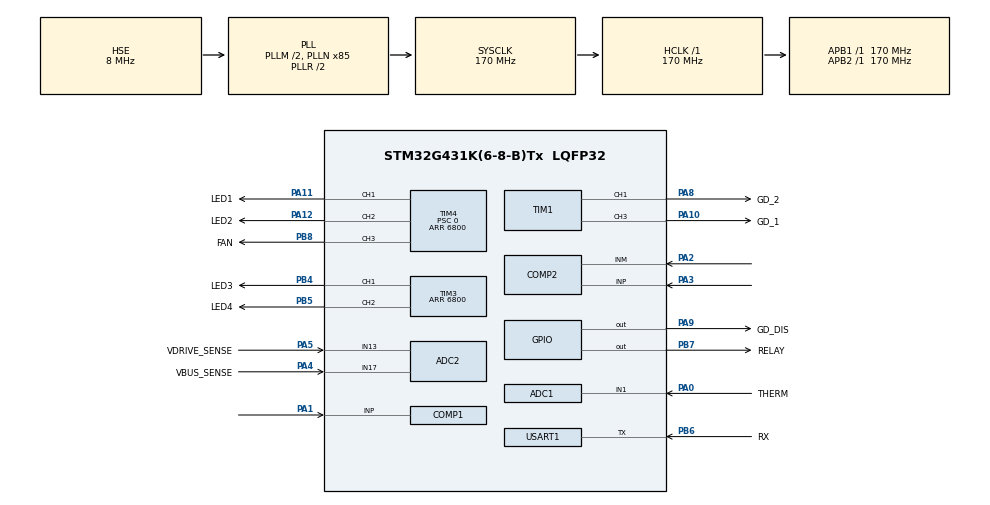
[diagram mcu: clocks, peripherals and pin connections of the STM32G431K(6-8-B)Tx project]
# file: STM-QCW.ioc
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ADC1.Channel-0\#ChannelRegularConversion=ADC_CHANNEL_1
ADC1.Channel-1\#ChannelRegularConversion=ADC_CHANNEL_TEMPSENSOR_ADC1
ADC1.Channel-2\#ChannelRegularConversion=ADC_CHANNEL_VREFINT
ADC1.ClockPrescaler=ADC_CLOCK_ASYNC_DIV4
ADC1.ContinuousConvMode=DISABLE
ADC1.DMAContinuousRequests=ENABLE
ADC1.EOCSelection=ADC_EOC_SEQ_CONV
ADC1.ExternalTrigConv=ADC_EXTERNALTRIG_T15_TRGO
ADC1.NbrOfConversion=3
ADC1.NbrOfConversionFlag=1
ADC1.OffsetNumber-0\#ChannelRegularConversion=ADC_OFFSET_NONE
ADC1.OffsetNumber-1\#ChannelRegularConversion=ADC_OFFSET_NONE
ADC1.OffsetNumber-2\#ChannelRegularConversion=ADC_OFFSET_NONE
ADC1.OversamplingMode=DISABLE
ADC1.Rank-0\#ChannelRegularConversion=1
ADC1.Rank-1\#ChannelRegularConversion=2
ADC1.Rank-2\#ChannelRegularConversion=3
ADC1.SamplingTime-0\#ChannelRegularConversion=ADC_SAMPLETIME_92CYCLES_5
ADC1.SamplingTime-1\#ChannelRegularConversion=ADC_SAMPLETIME_92CYCLES_5
ADC1.SamplingTime-2\#ChannelRegularConversion=ADC_SAMPLETIME_92CYCLES_5
ADC1.master=1
ADC2.Channel-0\#ChannelRegularConversion=ADC_CHANNEL_17
ADC2.Channel-1\#ChannelRegularConversion=ADC_CHANNEL_13
ADC2.ClockPrescaler=ADC_CLOCK_ASYNC_DIV4
ADC2.ContinuousConvMode=DISABLE
ADC2.DMAContinuousRequests=ENABLE
ADC2.ExternalTrigConv=ADC_EXTERNALTRIG_T15_TRGO
ADC2.NbrOfConversion=2
ADC2.NbrOfConversionFlag=1
ADC2.OffsetNumber-0\#ChannelRegularConversion=ADC_OFFSET_NONE
ADC2.OffsetNumber-1\#ChannelRegularConversion=ADC_OFFSET_NONE
ADC2.Rank-0\#ChannelRegularConversion=1
ADC2.Rank-1\#ChannelRegularConversion=2
ADC2.SamplingTime-0\#ChannelRegularConversion=ADC_SAMPLETIME_247CYCLES_5
ADC2.SamplingTime-1\#ChannelRegularConversion=ADC_SAMPLETIME_92CYCLES_5
COMP1.Hysteresis=COMP_HYSTERESIS_10MV
COMP1.TriggerMode=COMP_TRIGGERMODE_IT_RISING
COMP2.Hysteresis=COMP_HYSTERESIS_70MV
COMP2.TriggerMode=COMP_TRIGGERMODE_NONE
Dma.ADC1.0.Direction=DMA_PERIPH_TO_MEMORY
Dma.ADC1.0.EventEnable=DISABLE
Dma.ADC1.0.Instance=DMA1_Channel1
Dma.ADC1.0.MemDataAlignment=DMA_MDATAALIGN_HALFWORD
Dma.ADC1.0.MemInc=DMA_MINC_ENABLE
Dma.ADC1.0.Mode=DMA_CIRCULAR
Dma.ADC1.0.PeriphDataAlignment=DMA_PDATAALIGN_HALFWORD
Dma.ADC1.0.PeriphInc=DMA_PINC_DISABLE
Dma.ADC1.0.Polarity=HAL_DMAMUX_REQ_GEN_RISING
Dma.ADC1.0.Priority=DMA_PRIORITY_LOW
Dma.ADC1.0.RequestNumber=1
Dma.ADC1.0.SignalID=NONE
Dma.ADC1.0.SyncEnable=DISABLE
Dma.ADC1.0.SyncPolarity=HAL_DMAMUX_SYNC_NO_EVENT
Dma.ADC1.0.SyncRequestNumber=1
Dma.ADC1.0.SyncSignalID=NONE
Dma.ADC2.1.Direction=DMA_PERIPH_TO_MEMORY
Dma.ADC2.1.EventEnable=DISABLE
Dma.ADC2.1.Instance=DMA1_Channel2
Dma.ADC2.1.MemDataAlignment=DMA_MDATAALIGN_HALFWORD
Dma.ADC2.1.MemInc=DMA_MINC_ENABLE
Dma.ADC2.1.Mode=DMA_CIRCULAR
Dma.ADC2.1.PeriphDataAlignment=DMA_PDATAALIGN_HALFWORD
Dma.ADC2.1.PeriphInc=DMA_PINC_DISABLE
Dma.ADC2.1.Polarity=HAL_DMAMUX_REQ_GEN_RISING
Dma.ADC2.1.Priority=DMA_PRIORITY_LOW
Dma.ADC2.1.RequestNumber=1
Dma.ADC2.1.SignalID=NONE
Dma.ADC2.1.SyncEnable=DISABLE
Dma.ADC2.1.SyncPolarity=HAL_DMAMUX_SYNC_NO_EVENT
Dma.ADC2.1.SyncRequestNumber=1
Dma.ADC2.1.SyncSignalID=NONE
Dma.Request0=ADC1
Dma.Request1=ADC2
Mcu.Family=STM32G4
Mcu.Name=STM32G431K(6-8-B)Tx
Mcu.Package=LQFP32
NVIC.ADC1_2_IRQn=true\:0\:0\:false\:false\:true\:true\:true\:true
NVIC.COMP1_2_3_IRQn=true\:0\:0\:false\:false\:true\:false\:true\:true
NVIC.DMA1_Channel1_IRQn=true\:0\:0\:false\:false\:true\:false\:true\:true
NVIC.DMA1_Channel2_IRQn=true\:0\:0\:false\:false\:true\:false\:true\:true
NVIC.PriorityGroup=NVIC_PRIORITYGROUP_4
NVIC.TIM1_BRK_TIM15_IRQn=true\:0\:0\:false\:false\:true\:true\:true\:true
NVIC.TIM1_CC_IRQn=true\:0\:0\:false\:false\:true\:true\:true\:true
NVIC.TIM1_TRG_COM_TIM17_IRQn=true\:0\:0\:false\:false\:true\:true\:true\:true
NVIC.TIM1_UP_TIM16_IRQn=true\:0\:0\:false\:false\:true\:true\:true\:true
NVIC.TIM2_IRQn=true\:0\:0\:false\:false\:true\:true\:true\:true
NVIC.TIM6_DAC_IRQn=true\:0\:0\:false\:false\:true\:true\:true\:true
NVIC.TIM7_IRQn=true\:0\:0\:false\:false\:true\:true\:true\:true
NVIC.TIM8_BRK_IRQn=true\:0\:0\:false\:false\:true\:true\:true\:true
NVIC.TIM8_CC_IRQn=true\:0\:0\:false\:false\:true\:true\:true\:true
NVIC.TIM8_TRG_COM_IRQn=true\:0\:0\:false\:false\:true\:true\:true\:true
NVIC.TIM8_UP_IRQn=true\:0\:0\:false\:false\:true\:true\:true\:true
NVIC.USART1_IRQn=true\:0\:0\:false\:false\:true\:true\:true\:true
PA0.GPIO_Label=THERM
PA0.Mode=IN1-Single-Ended
PA0.Signal=ADC1_IN1
PA1.Mode=INP
PA1.Signal=COMP1_INP
PA10.GPIO_Label=GD_1
PA10.Signal=S_TIM1_CH3
PA11.GPIO_Label=LED1
PA11.Signal=S_TIM4_CH1
PA12.GPIO_Label=LED2
PA12.Signal=S_TIM4_CH2
PA13.Mode=JTAG_4_pins
PA13.Signal=SYS_JTMS-SWDIO
PA14.Mode=JTAG_4_pins
PA14.Signal=SYS_JTCK-SWCLK
PA15.Mode=JTAG_4_pins
PA15.Signal=SYS_JTDI
PA2.Mode=INM
PA2.Signal=COMP2_INM
PA3.Mode=INP
PA3.Signal=COMP2_INP
PA4.GPIO_Label=VBUS_SENSE
PA4.Mode=IN17-Single-Ended
PA4.Signal=ADC2_IN17
PA5.GPIO_Label=VDRIVE_SENSE
PA5.Mode=IN13-Single-Ended
PA5.Signal=ADC2_IN13
PA8.GPIO_Label=GD_2
PA8.Signal=S_TIM1_CH1
PA9.GPIO_Label=GD_DIS
PA9.Signal=GPIO_Output
PB3.Mode=JTAG_4_pins
PB3.Signal=SYS_JTDO-SWO
PB4.GPIO_Label=LED3
PB4.Signal=S_TIM3_CH1
PB5.GPIO_Label=LED4
PB5.Signal=S_TIM3_CH2
PB6.GPIO_Label=RX
PB6.GPIO_PuPd=GPIO_PULLUP
PB6.Mode=Half_duplex(single_wire_mode)
PB6.Signal=USART1_TX
PB7.GPIO_Label=RELAY
PB7.Signal=GPIO_Output
PB8-BOOT0.GPIO_Label=FAN
PB8-BOOT0.GPIO_PuPd=GPIO_PULLDOWN
PB8-BOOT0.Signal=S_TIM4_CH3
PF0-OSC_IN.Mode=HSE-External-Oscillator
PF0-OSC_IN.Signal=RCC_OSC_IN
PF1-OSC_OUT.Mode=HSE-External-Oscillator
PF1-OSC_OUT.Signal=RCC_OSC_OUT
ProjectManager.HeapSize=0x200
ProjectManager.StackSize=0x400
ProjectManager.TargetToolchain=STM32CubeIDE
RCC.ADC12Freq_Value=170000000
RCC.AHBFreq_Value=170000000
RCC.APB1Freq_Value=170000000
RCC.APB1TimFreq_Value=170000000
RCC.APB2Freq_Value=170000000
RCC.APB2TimFreq_Value=170000000
RCC.CortexFreq_Value=170000000
RCC.EXTERNAL_CLOCK_VALUE=12288000
RCC.HCLKFreq_Value=170000000
RCC.HSE_Timout=1000
RCC.HSE_VALUE=8000000
RCC.HSI48_VALUE=48000000
RCC.HSI_VALUE=16000000
RCC.LSE_VALUE=32768
RCC.PLLM=RCC_PLLM_DIV2
RCC.PLLN=85
RCC.PLLSourceVirtual=RCC_PLLSOURCE_HSE
RCC.SYSCLKFreq_VALUE=170000000
RCC.SYSCLKSource=RCC_SYSCLKSOURCE_PLLCLK
RCC.USBFreq_Value=170000000
RCC.VCOOutputFreq_Value=340000000
SH.S_TIM1_CH1.0=TIM1_CH1,PWM Generation1 CH1
SH.S_TIM1_CH3.0=TIM1_CH3,PWM Generation3 CH3
SH.S_TIM3_CH1.0=TIM3_CH1,PWM Generation1 CH1
SH.S_TIM3_CH2.0=TIM3_CH2,PWM Generation2 CH2
SH.S_TIM4_CH1.0=TIM4_CH1,PWM Generation1 CH1
SH.S_TIM4_CH2.0=TIM4_CH2,PWM Generation2 CH2
SH.S_TIM4_CH3.0=TIM4_CH3,PWM Generation3 CH3
TIM1.Channel-PWM\ Generation1\ CH1=TIM_CHANNEL_1
TIM1.Channel-PWM\ Generation2\ No\ Output=TIM_CHANNEL_2
TIM1.Channel-PWM\ Generation3\ CH3=TIM_CHANNEL_3
TIM1.Channel-PWM\ Generation4\ No\ Output=TIM_CHANNEL_4
TIM1.CounterMode=TIM_COUNTERMODE_CENTERALIGNED1
TIM1.OCMode_PWM-PWM\ Generation1\ CH1=TIM_OCMODE_ASSYMETRIC_PWM1
TIM1.OCMode_PWM-PWM\ Generation2\ No\ Output=TIM_OCMODE_ASSYMETRIC_PWM1
TIM1.OCMode_PWM-PWM\ Generation3\ CH3=TIM_OCMODE_ASSYMETRIC_PWM1
TIM1.OCMode_PWM-PWM\ Generation4\ No\ Output=TIM_OCMODE_ASSYMETRIC_PWM1
TIM1.OCPolarity_3=TIM_OCPOLARITY_HIGH
TIM1.OCPolarity_4=TIM_OCPOLARITY_HIGH
TIM1.TIM_MasterOutputTrigger=TIM_TRGO_ENABLE
TIM1.TIM_MasterOutputTrigger2=TIM_TRGO2_OC5REF
TIM15.PeriodNoDither=100-1
TIM15.Prescaler=170-1
TIM15.TIM_MasterOutputTrigger=TIM_TRGO_UPDATE
TIM2.Channel-Input_Capture1_from_TI1_REMAP_TIM2=TIM_CHANNEL_1
TIM2.TIM2_TI1_REMAP-Input_Capture1_from_TI1_REMAP_TIM2=TIM_TIM2_TI1_COMP2
TIM3.Channel-PWM\ Generation1\ CH1=TIM_CHANNEL_1
TIM3.Channel-PWM\ Generation2\ CH2=TIM_CHANNEL_2
TIM3.PeriodNoDither=6800
TIM4.Channel-PWM\ Generation1\ CH1=TIM_CHANNEL_1
TIM4.Channel-PWM\ Generation2\ CH2=TIM_CHANNEL_2
TIM4.Channel-PWM\ Generation3\ CH3=TIM_CHANNEL_3
TIM4.OCMode_PWM-PWM\ Generation3\ CH3=TIM_OCMODE_PWM2
TIM4.PeriodNoDither=6800
TIM4.Prescaler=0
TIM7.PeriodNoDither=10000-1
TIM7.Prescaler=1700-1
TIM8.Channel-PWM\ Generation1\ No\ Output=TIM_CHANNEL_1
TIM8.CounterMode=TIM_COUNTERMODE_CENTERALIGNED1
TIM8.TIM8_ETR_REMAP-TriggerSource_ETR_Remap_TIM8=TIM_TIM8_ETR_COMP2
USART1.Mode=MODE_RX
USART1.RxPinLevelInvertParam=ADVFEATURE_RXINV_DISABLE
USART1.TxPinLevelInvertParam=ADVFEATURE_TXINV_DISABLE
USART1.VirtualMode-Half_duplex(single_wire_mode)=VM_ASYNC
VP_ADC1_TempSens_Input.Mode=IN-TempSens
VP_ADC1_Vref_Input.Mode=IN-Vrefint
VP_COMP1_VS_DAC1OUT1.Mode=INM_DAC1OUT1
VP_DAC1_VS_DACI1.Mode=DAC_OUT1_Int
VP_SYS_VS_DBSignals.Mode=DisableDeadBatterySignals
VP_TIM15_VS_ClockSourceINT.Mode=Internal
VP_TIM1_VS_ClockSourceINT.Mode=Internal
VP_TIM1_VS_no_output2.Mode=PWM Generation2 No Output
VP_TIM1_VS_no_output4.Mode=PWM Generation4 No Output
VP_TIM2_VS_ClockSourceINT.Mode=Internal
VP_TIM2_VS_NoInput1.Mode=Input_Capture1_from_TI1_REMAP_TIM2
VP_TIM3_VS_ClockSourceINT.Mode=Internal
VP_TIM4_VS_ClockSourceINT.Mode=Internal
VP_TIM6_VS_ClockSourceINT.Mode=Enable_Timer
VP_TIM7_VS_ClockSourceINT.Mode=Enable_Timer
VP_TIM8_VS_ClockSourceINT.Mode=Internal
VP_TIM8_VS_ControllerModeReset.Mode=Reset Mode
VP_TIM8_VS_NoETR.Mode=TriggerSource_ETR_Remap_TIM8
VP_TIM8_VS_no_output1.Mode=PWM Generation1 No Output
board=custom

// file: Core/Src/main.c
/* USER CODE BEGIN Header */
/**
  ******************************************************************************
  * @file           : main.c
  * @brief          : Main program body
  ******************************************************************************
  * @attention
  *
  * Copyright (c) 2025 STMicroelectronics.
  * All rights reserved.
  *
  * This software is licensed under terms that can be found in the LICENSE file
  * in the root directory of this software component.
  * If no LICENSE file comes with this software, it is provided AS-IS.
  *
  ******************************************************************************
  */
/* USER CODE END Header */
#include "main.h"

ADC_HandleTypeDef hadc1;
ADC_HandleTypeDef hadc2;
DMA_HandleTypeDef hdma_adc1;
DMA_HandleTypeDef hdma_adc2;

COMP_HandleTypeDef hcomp1;
COMP_HandleTypeDef hcomp2;

DAC_HandleTypeDef hdac1;

TIM_HandleTypeDef htim1;
TIM_HandleTypeDef htim2;
TIM_HandleTypeDef htim3;
TIM_HandleTypeDef htim4;
TIM_HandleTypeDef htim6;
TIM_HandleTypeDef htim7;
TIM_HandleTypeDef htim8;
TIM_HandleTypeDef htim15;

UART_HandleTypeDef huart1;

void SystemClock_Config(void);
static void MX_GPIO_Init(void);
static void MX_DMA_Init(void);
static void MX_ADC1_Init(void);
static void MX_ADC2_Init(void);
static void MX_COMP1_Init(void);
static void MX_COMP2_Init(void);
static void MX_DAC1_Init(void);
static void MX_TIM1_Init(void);
static void MX_USART1_UART_Init(void);
static void MX_TIM2_Init(void);
static void MX_TIM6_Init(void);
static void MX_TIM4_Init(void);
static void MX_TIM3_Init(void);
static void MX_TIM7_Init(void);
static void MX_TIM8_Init(void);
static void MX_TIM15_Init(void);

int main(void)
{

  /* MCU Configuration--------------------------------------------------------*/

  /* Reset of all peripherals, Initializes the Flash interface and the Systick. */
  HAL_Init();

  /* Configure the system clock */
  SystemClock_Config();

  /* Initialize all configured peripherals */
  MX_GPIO_Init();
  MX_DMA_Init();
  MX_ADC1_Init();
  MX_ADC2_Init();
  MX_COMP1_Init();
  MX_COMP2_Init();
  MX_DAC1_Init();
  MX_TIM1_Init();
  MX_USART1_UART_Init();
  MX_TIM2_Init();
  MX_TIM6_Init();
  MX_TIM4_Init();
  MX_TIM3_Init();
  MX_TIM7_Init();
  MX_TIM8_Init();
  MX_TIM15_Init();
  /* USER CODE BEGIN 2 */

  QCW_Init();
  HAL_Delay(1000);
  /* USER CODE END 2 */

  /* Infinite loop */
  while (1)
  {

    /* USER CODE BEGIN 3 */
	  	 HAL_Delay(100);
	  	 StartPulse(1.0f, 150.0f, 30.0f);

  }
  /* USER CODE END 3 */
}

void SystemClock_Config(void)
{
  RCC_OscInitTypeDef RCC_OscInitStruct = {0};
  RCC_ClkInitTypeDef RCC_ClkInitStruct = {0};

  /** Configure the main internal regulator output voltage
  */
  HAL_PWREx_ControlVoltageScaling(PWR_REGULATOR_VOLTAGE_SCALE1_BOOST);

  /** Initializes the RCC Oscillators according to the specified parameters
  * in the RCC_OscInitTypeDef structure.
  */
  RCC_OscInitStruct.OscillatorType = RCC_OSCILLATORTYPE_HSE;
  RCC_OscInitStruct.HSEState = RCC_HSE_ON;
  RCC_OscInitStruct.PLL.PLLState = RCC_PLL_ON;
  RCC_OscInitStruct.PLL.PLLSource = RCC_PLLSOURCE_HSE;
  RCC_OscInitStruct.PLL.PLLM = RCC_PLLM_DIV2;
  RCC_OscInitStruct.PLL.PLLN = 85;
  RCC_OscInitStruct.PLL.PLLP = RCC_PLLP_DIV2;
  RCC_OscInitStruct.PLL.PLLQ = RCC_PLLQ_DIV2;
  RCC_OscInitStruct.PLL.PLLR = RCC_PLLR_DIV2;
  if (HAL_RCC_OscConfig(&RCC_OscInitStruct) != HAL_OK)
  {
    Error_Handler();
  }

  /** Initializes the CPU, AHB and APB buses clocks
  */
  RCC_ClkInitStruct.ClockType = RCC_CLOCKTYPE_HCLK|RCC_CLOCKTYPE_SYSCLK
                              |RCC_CLOCKTYPE_PCLK1|RCC_CLOCKTYPE_PCLK2;
  RCC_ClkInitStruct.SYSCLKSource = RCC_SYSCLKSOURCE_PLLCLK;
  RCC_ClkInitStruct.AHBCLKDivider = RCC_SYSCLK_DIV1;
  RCC_ClkInitStruct.APB1CLKDivider = RCC_HCLK_DIV1;
  RCC_ClkInitStruct.APB2CLKDivider = RCC_HCLK_DIV1;

  if (HAL_RCC_ClockConfig(&RCC_ClkInitStruct, FLASH_LATENCY_4) != HAL_OK)
  {
    Error_Handler();
  }
}

static void MX_ADC1_Init(void)
{

  ADC_MultiModeTypeDef multimode = {0};
  ADC_ChannelConfTypeDef sConfig = {0};

  /** Common config
  */
  hadc1.Instance = ADC1;
  hadc1.Init.ClockPrescaler = ADC_CLOCK_ASYNC_DIV4;
  hadc1.Init.Resolution = ADC_RESOLUTION_12B;
  hadc1.Init.DataAlign = ADC_DATAALIGN_RIGHT;
  hadc1.Init.GainCompensation = 0;
  hadc1.Init.ScanConvMode = ADC_SCAN_ENABLE;
  hadc1.Init.EOCSelection = ADC_EOC_SEQ_CONV;
  hadc1.Init.LowPowerAutoWait = DISABLE;
  hadc1.Init.ContinuousConvMode = DISABLE;
  hadc1.Init.NbrOfConversion = 3;
  hadc1.Init.DiscontinuousConvMode = DISABLE;
  hadc1.Init.ExternalTrigConv = ADC_EXTERNALTRIG_T15_TRGO;
  hadc1.Init.ExternalTrigConvEdge = ADC_EXTERNALTRIGCONVEDGE_RISING;
  hadc1.Init.DMAContinuousRequests = ENABLE;
  hadc1.Init.Overrun = ADC_OVR_DATA_PRESERVED;
  hadc1.Init.OversamplingMode = DISABLE;
  if (HAL_ADC_Init(&hadc1) != HAL_OK)
  {
    Error_Handler();
  }

  /** Configure the ADC multi-mode
  */
  multimode.Mode = ADC_MODE_INDEPENDENT;
  if (HAL_ADCEx_MultiModeConfigChannel(&hadc1, &multimode) != HAL_OK)
  {
    Error_Handler();
  }

  /** Configure Regular Channel
  */
  sConfig.Channel = ADC_CHANNEL_1;
  sConfig.Rank = ADC_REGULAR_RANK_1;
  sConfig.SamplingTime = ADC_SAMPLETIME_92CYCLES_5;
  sConfig.SingleDiff = ADC_SINGLE_ENDED;
  sConfig.OffsetNumber = ADC_OFFSET_NONE;
  sConfig.Offset = 0;
  if (HAL_ADC_ConfigChannel(&hadc1, &sConfig) != HAL_OK)
  {
    Error_Handler();
  }

  /** Configure Regular Channel
  */
  sConfig.Channel = ADC_CHANNEL_TEMPSENSOR_ADC1;
  sConfig.Rank = ADC_REGULAR_RANK_2;
  if (HAL_ADC_ConfigChannel(&hadc1, &sConfig) != HAL_OK)
  {
    Error_Handler();
  }

  /** Configure Regular Channel
  */
  sConfig.Channel = ADC_CHANNEL_VREFINT;
  sConfig.Rank = ADC_REGULAR_RANK_3;
  if (HAL_ADC_ConfigChannel(&hadc1, &sConfig) != HAL_OK)
  {
    Error_Handler();
  }

}

static void MX_ADC2_Init(void)
{

  ADC_ChannelConfTypeDef sConfig = {0};

  /** Common config
  */
  hadc2.Instance = ADC2;
  hadc2.Init.ClockPrescaler = ADC_CLOCK_ASYNC_DIV4;
  hadc2.Init.Resolution = ADC_RESOLUTION_12B;
  hadc2.Init.DataAlign = ADC_DATAALIGN_RIGHT;
  hadc2.Init.GainCompensation = 0;
  hadc2.Init.ScanConvMode = ADC_SCAN_ENABLE;
  hadc2.Init.EOCSelection = ADC_EOC_SINGLE_CONV;
  hadc2.Init.LowPowerAutoWait = DISABLE;
  hadc2.Init.ContinuousConvMode = DISABLE;
  hadc2.Init.NbrOfConversion = 2;
  hadc2.Init.DiscontinuousConvMode = DISABLE;
  hadc2.Init.ExternalTrigConv = ADC_EXTERNALTRIG_T15_TRGO;
  hadc2.Init.ExternalTrigConvEdge = ADC_EXTERNALTRIGCONVEDGE_RISING;
  hadc2.Init.DMAContinuousRequests = ENABLE;
  hadc2.Init.Overrun = ADC_OVR_DATA_PRESERVED;
  hadc2.Init.OversamplingMode = DISABLE;
  if (HAL_ADC_Init(&hadc2) != HAL_OK)
  {
    Error_Handler();
  }

  /** Configure Regular Channel
  */
  sConfig.Channel = ADC_CHANNEL_17;
  sConfig.Rank = ADC_REGULAR_RANK_1;
  sConfig.SamplingTime = ADC_SAMPLETIME_247CYCLES_5;
  sConfig.SingleDiff = ADC_SINGLE_ENDED;
  sConfig.OffsetNumber = ADC_OFFSET_NONE;
  sConfig.Offset = 0;
  if (HAL_ADC_ConfigChannel(&hadc2, &sConfig) != HAL_OK)
  {
    Error_Handler();
  }

  /** Configure Regular Channel
  */
  sConfig.Channel = ADC_CHANNEL_13;
  sConfig.Rank = ADC_REGULAR_RANK_2;
  sConfig.SamplingTime = ADC_SAMPLETIME_92CYCLES_5;
  if (HAL_ADC_ConfigChannel(&hadc2, &sConfig) != HAL_OK)
  {
    Error_Handler();
  }

}

static void MX_COMP1_Init(void)
{

  hcomp1.Instance = COMP1;
  hcomp1.Init.InputPlus = COMP_INPUT_PLUS_IO1;
  hcomp1.Init.InputMinus = COMP_INPUT_MINUS_DAC1_CH1;
  hcomp1.Init.OutputPol = COMP_OUTPUTPOL_NONINVERTED;
  hcomp1.Init.Hysteresis = COMP_HYSTERESIS_10MV;
  hcomp1.Init.BlankingSrce = COMP_BLANKINGSRC_NONE;
  hcomp1.Init.TriggerMode = COMP_TRIGGERMODE_IT_RISING;
  if (HAL_COMP_Init(&hcomp1) != HAL_OK)
  {
    Error_Handler();
  }

}

static void MX_COMP2_Init(void)
{

  hcomp2.Instance = COMP2;
  hcomp2.Init.InputPlus = COMP_INPUT_PLUS_IO2;
  hcomp2.Init.InputMinus = COMP_INPUT_MINUS_IO2;
  hcomp2.Init.OutputPol = COMP_OUTPUTPOL_NONINVERTED;
  hcomp2.Init.Hysteresis = COMP_HYSTERESIS_70MV;
  hcomp2.Init.BlankingSrce = COMP_BLANKINGSRC_NONE;
  hcomp2.Init.TriggerMode = COMP_TRIGGERMODE_NONE;
  if (HAL_COMP_Init(&hcomp2) != HAL_OK)
  {
    Error_Handler();
  }

}

static void MX_DAC1_Init(void)
{

  DAC_ChannelConfTypeDef sConfig = {0};

  /** DAC Initialization
  */
  hdac1.Instance = DAC1;
  if (HAL_DAC_Init(&hdac1) != HAL_OK)
  {
    Error_Handler();
  }

  /** DAC channel OUT1 config
  */
  sConfig.DAC_HighFrequency = DAC_HIGH_FREQUENCY_INTERFACE_MODE_AUTOMATIC;
  sConfig.DAC_DMADoubleDataMode = DISABLE;
  sConfig.DAC_SignedFormat = DISABLE;
  sConfig.DAC_SampleAndHold = DAC_SAMPLEANDHOLD_DISABLE;
  sConfig.DAC_Trigger = DAC_TRIGGER_NONE;
  sConfig.DAC_Trigger2 = DAC_TRIGGER_NONE;
  sConfig.DAC_OutputBuffer = DAC_OUTPUTBUFFER_DISABLE;
  sConfig.DAC_ConnectOnChipPeripheral = DAC_CHIPCONNECT_INTERNAL;
  sConfig.DAC_UserTrimming = DAC_TRIMMING_FACTORY;
  if (HAL_DAC_ConfigChannel(&hdac1, &sConfig, DAC_CHANNEL_1) != HAL_OK)
  {
    Error_Handler();
  }

}

static void MX_TIM1_Init(void)
{

  TIM_ClockConfigTypeDef sClockSourceConfig = {0};
  TIM_MasterConfigTypeDef sMasterConfig = {0};
  TIM_OC_InitTypeDef sConfigOC = {0};
  TIM_BreakDeadTimeConfigTypeDef sBreakDeadTimeConfig = {0};

  htim1.Instance = TIM1;
  htim1.Init.Prescaler = 0;
  htim1.Init.CounterMode = TIM_COUNTERMODE_CENTERALIGNED1;
  htim1.Init.Period = 65535;
  htim1.Init.ClockDivision = TIM_CLOCKDIVISION_DIV1;
  htim1.Init.RepetitionCounter = 0;
  htim1.Init.AutoReloadPreload = TIM_AUTORELOAD_PRELOAD_DISABLE;
  if (HAL_TIM_Base_Init(&htim1) != HAL_OK)
  {
    Error_Handler();
  }
  sClockSourceConfig.ClockSource = TIM_CLOCKSOURCE_INTERNAL;
  if (HAL_TIM_ConfigClockSource(&htim1, &sClockSourceConfig) != HAL_OK)
  {
    Error_Handler();
  }
  if (HAL_TIM_PWM_Init(&htim1) != HAL_OK)
  {
    Error_Handler();
  }
  sMasterConfig.MasterOutputTrigger = TIM_TRGO_ENABLE;
  sMasterConfig.MasterOutputTrigger2 = TIM_TRGO2_OC5REF;
  sMasterConfig.MasterSlaveMode = TIM_MASTERSLAVEMODE_DISABLE;
  if (HAL_TIMEx_MasterConfigSynchronization(&htim1, &sMasterConfig) != HAL_OK)
  {
    Error_Handler();
  }
  sConfigOC.OCMode = TIM_OCMODE_ASSYMETRIC_PWM1;
  sConfigOC.Pulse = 0;
  sConfigOC.OCPolarity = TIM_OCPOLARITY_HIGH;
  sConfigOC.OCNPolarity = TIM_OCNPOLARITY_HIGH;
  sConfigOC.OCFastMode = TIM_OCFAST_DISABLE;
  sConfigOC.OCIdleState = TIM_OCIDLESTATE_RESET;
  sConfigOC.OCNIdleState = TIM_OCNIDLESTATE_RESET;
  if (HAL_TIM_PWM_ConfigChannel(&htim1, &sConfigOC, TIM_CHANNEL_1) != HAL_OK)
  {
    Error_Handler();
  }
  if (HAL_TIM_PWM_ConfigChannel(&htim1, &sConfigOC, TIM_CHANNEL_2) != HAL_OK)
  {
    Error_Handler();
  }
  if (HAL_TIM_PWM_ConfigChannel(&htim1, &sConfigOC, TIM_CHANNEL_3) != HAL_OK)
  {
    Error_Handler();
  }
  if (HAL_TIM_PWM_ConfigChannel(&htim1, &sConfigOC, TIM_CHANNEL_4) != HAL_OK)
  {
    Error_Handler();
  }
  sBreakDeadTimeConfig.OffStateRunMode = TIM_OSSR_DISABLE;
  sBreakDeadTimeConfig.OffStateIDLEMode = TIM_OSSI_DISABLE;
  sBreakDeadTimeConfig.LockLevel = TIM_LOCKLEVEL_OFF;
  sBreakDeadTimeConfig.DeadTime = 0;
  sBreakDeadTimeConfig.BreakState = TIM_BREAK_DISABLE;
  sBreakDeadTimeConfig.BreakPolarity = TIM_BREAKPOLARITY_HIGH;
  sBreakDeadTimeConfig.BreakFilter = 0;
  sBreakDeadTimeConfig.BreakAFMode = TIM_BREAK_AFMODE_INPUT;
  sBreakDeadTimeConfig.Break2State = TIM_BREAK2_DISABLE;
  sBreakDeadTimeConfig.Break2Polarity = TIM_BREAK2POLARITY_HIGH;
  sBreakDeadTimeConfig.Break2Filter = 0;
  sBreakDeadTimeConfig.Break2AFMode = TIM_BREAK_AFMODE_INPUT;
  sBreakDeadTimeConfig.AutomaticOutput = TIM_AUTOMATICOUTPUT_DISABLE;
  if (HAL_TIMEx_ConfigBreakDeadTime(&htim1, &sBreakDeadTimeConfig) != HAL_OK)
  {
    Error_Handler();
  }
  HAL_TIM_MspPostInit(&htim1);

}

static void MX_TIM2_Init(void)
{

  TIM_ClockConfigTypeDef sClockSourceConfig = {0};
  TIM_MasterConfigTypeDef sMasterConfig = {0};
  TIM_IC_InitTypeDef sConfigIC = {0};

  htim2.Instance = TIM2;
  htim2.Init.Prescaler = 0;
  htim2.Init.CounterMode = TIM_COUNTERMODE_UP;
  htim2.Init.Period = 4294967295;
  htim2.Init.ClockDivision = TIM_CLOCKDIVISION_DIV1;
  htim2.Init.AutoReloadPreload = TIM_AUTORELOAD_PRELOAD_DISABLE;
  if (HAL_TIM_Base_Init(&htim2) != HAL_OK)
  {
    Error_Handler();
  }
  sClockSourceConfig.ClockSource = TIM_CLOCKSOURCE_INTERNAL;
  if (HAL_TIM_ConfigClockSource(&htim2, &sClockSourceConfig) != HAL_OK)
  {
    Error_Handler();
  }
  if (HAL_TIM_IC_Init(&htim2) != HAL_OK)
  {
    Error_Handler();
  }
  sMasterConfig.MasterOutputTrigger = TIM_TRGO_RESET;
  sMasterConfig.MasterSlaveMode = TIM_MASTERSLAVEMODE_DISABLE;
  if (HAL_TIMEx_MasterConfigSynchronization(&htim2, &sMasterConfig) != HAL_OK)
  {
    Error_Handler();
  }
  sConfigIC.ICPolarity = TIM_INPUTCHANNELPOLARITY_RISING;
  sConfigIC.ICSelection = TIM_ICSELECTION_DIRECTTI;
  sConfigIC.ICPrescaler = TIM_ICPSC_DIV1;
  sConfigIC.ICFilter = 0;
  if (HAL_TIM_IC_ConfigChannel(&htim2, &sConfigIC, TIM_CHANNEL_1) != HAL_OK)
  {
    Error_Handler();
  }
  if (HAL_TIMEx_TISelection(&htim2, TIM_TIM2_TI1_COMP2, TIM_CHANNEL_1) != HAL_OK)
  {
    Error_Handler();
  }

}

static void MX_TIM3_Init(void)
{

  TIM_ClockConfigTypeDef sClockSourceConfig = {0};
  TIM_MasterConfigTypeDef sMasterConfig = {0};
  TIM_OC_InitTypeDef sConfigOC = {0};

  htim3.Instance = TIM3;
  htim3.Init.Prescaler = 0;
  htim3.Init.CounterMode = TIM_COUNTERMODE_UP;
  htim3.Init.Period = 6800;
  htim3.Init.ClockDivision = TIM_CLOCKDIVISION_DIV1;
  htim3.Init.AutoReloadPreload = TIM_AUTORELOAD_PRELOAD_DISABLE;
  if (HAL_TIM_Base_Init(&htim3) != HAL_OK)
  {
    Error_Handler();
  }
  sClockSourceConfig.ClockSource = TIM_CLOCKSOURCE_INTERNAL;
  if (HAL_TIM_ConfigClockSource(&htim3, &sClockSourceConfig) != HAL_OK)
  {
    Error_Handler();
  }
  if (HAL_TIM_PWM_Init(&htim3) != HAL_OK)
  {
    Error_Handler();
  }
  sMasterConfig.MasterOutputTrigger = TIM_TRGO_RESET;
  sMasterConfig.MasterSlaveMode = TIM_MASTERSLAVEMODE_DISABLE;
  if (HAL_TIMEx_MasterConfigSynchronization(&htim3, &sMasterConfig) != HAL_OK)
  {
    Error_Handler();
  }
  sConfigOC.OCMode = TIM_OCMODE_PWM1;
  sConfigOC.Pulse = 0;
  sConfigOC.OCPolarity = TIM_OCPOLARITY_HIGH;
  sConfigOC.OCFastMode = TIM_OCFAST_DISABLE;
  if (HAL_TIM_PWM_ConfigChannel(&htim3, &sConfigOC, TIM_CHANNEL_1) != HAL_OK)
  {
    Error_Handler();
  }
  if (HAL_TIM_PWM_ConfigChannel(&htim3, &sConfigOC, TIM_CHANNEL_2) != HAL_OK)
  {
    Error_Handler();
  }
  HAL_TIM_MspPostInit(&htim3);

}

static void MX_TIM4_Init(void)
{

  TIM_ClockConfigTypeDef sClockSourceConfig = {0};
  TIM_MasterConfigTypeDef sMasterConfig = {0};
  TIM_OC_InitTypeDef sConfigOC = {0};

  htim4.Instance = TIM4;
  htim4.Init.Prescaler = 0;
  htim4.Init.CounterMode = TIM_COUNTERMODE_UP;
  htim4.Init.Period = 6800;
  htim4.Init.ClockDivision = TIM_CLOCKDIVISION_DIV1;
  htim4.Init.AutoReloadPreload = TIM_AUTORELOAD_PRELOAD_DISABLE;
  if (HAL_TIM_Base_Init(&htim4) != HAL_OK)
  {
    Error_Handler();
  }
  sClockSourceConfig.ClockSource = TIM_CLOCKSOURCE_INTERNAL;
  if (HAL_TIM_ConfigClockSource(&htim4, &sClockSourceConfig) != HAL_OK)
  {
    Error_Handler();
  }
  if (HAL_TIM_PWM_Init(&htim4) != HAL_OK)
  {
    Error_Handler();
  }
  sMasterConfig.MasterOutputTrigger = TIM_TRGO_RESET;
  sMasterConfig.MasterSlaveMode = TIM_MASTERSLAVEMODE_DISABLE;
  if (HAL_TIMEx_MasterConfigSynchronization(&htim4, &sMasterConfig) != HAL_OK)
  {
    Error_Handler();
  }
  sConfigOC.OCMode = TIM_OCMODE_PWM1;
  sConfigOC.Pulse = 0;
  sConfigOC.OCPolarity = TIM_OCPOLARITY_HIGH;
  sConfigOC.OCFastMode = TIM_OCFAST_DISABLE;
  if (HAL_TIM_PWM_ConfigChannel(&htim4, &sConfigOC, TIM_CHANNEL_1) != HAL_OK)
  {
    Error_Handler();
  }
  if (HAL_TIM_PWM_ConfigChannel(&htim4, &sConfigOC, TIM_CHANNEL_2) != HAL_OK)
  {
    Error_Handler();
  }
  sConfigOC.OCMode = TIM_OCMODE_PWM2;
  if (HAL_TIM_PWM_ConfigChannel(&htim4, &sConfigOC, TIM_CHANNEL_3) != HAL_OK)
  {
    Error_Handler();
  }
  HAL_TIM_MspPostInit(&htim4);

}

static void MX_TIM6_Init(void)
{

  TIM_MasterConfigTypeDef sMasterConfig = {0};

  htim6.Instance = TIM6;
  htim6.Init.Prescaler = 0;
  htim6.Init.CounterMode = TIM_COUNTERMODE_UP;
  htim6.Init.Period = 65535;
  htim6.Init.AutoReloadPreload = TIM_AUTORELOAD_PRELOAD_DISABLE;
  if (HAL_TIM_Base_Init(&htim6) != HAL_OK)
  {
    Error_Handler();
  }
  sMasterConfig.MasterOutputTrigger = TIM_TRGO_RESET;
  sMasterConfig.MasterSlaveMode = TIM_MASTERSLAVEMODE_DISABLE;
  if (HAL_TIMEx_MasterConfigSynchronization(&htim6, &sMasterConfig) != HAL_OK)
  {
    Error_Handler();
  }

}

static void MX_TIM7_Init(void)
{

  TIM_MasterConfigTypeDef sMasterConfig = {0};

  htim7.Instance = TIM7;
  htim7.Init.Prescaler = 1700-1;
  htim7.Init.CounterMode = TIM_COUNTERMODE_UP;
  htim7.Init.Period = 9999;
  htim7.Init.AutoReloadPreload = TIM_AUTORELOAD_PRELOAD_DISABLE;
  if (HAL_TIM_Base_Init(&htim7) != HAL_OK)
  {
    Error_Handler();
  }
  sMasterConfig.MasterOutputTrigger = TIM_TRGO_RESET;
  sMasterConfig.MasterSlaveMode = TIM_MASTERSLAVEMODE_DISABLE;
  if (HAL_TIMEx_MasterConfigSynchronization(&htim7, &sMasterConfig) != HAL_OK)
  {
    Error_Handler();
  }

}

static void MX_TIM8_Init(void)
{

  TIM_ClockConfigTypeDef sClockSourceConfig = {0};
  TIM_SlaveConfigTypeDef sSlaveConfig = {0};
  TIM_MasterConfigTypeDef sMasterConfig = {0};
  TIM_OC_InitTypeDef sConfigOC = {0};
  TIM_BreakDeadTimeConfigTypeDef sBreakDeadTimeConfig = {0};

  htim8.Instance = TIM8;
  htim8.Init.Prescaler = 0;
  htim8.Init.CounterMode = TIM_COUNTERMODE_CENTERALIGNED1;
  htim8.Init.Period = 65535;
  htim8.Init.ClockDivision = TIM_CLOCKDIVISION_DIV1;
  htim8.Init.RepetitionCounter = 0;
  htim8.Init.AutoReloadPreload = TIM_AUTORELOAD_PRELOAD_DISABLE;
  if (HAL_TIM_Base_Init(&htim8) != HAL_OK)
  {
    Error_Handler();
  }
  sClockSourceConfig.ClockSource = TIM_CLOCKSOURCE_INTERNAL;
  if (HAL_TIM_ConfigClockSource(&htim8, &sClockSourceConfig) != HAL_OK)
  {
    Error_Handler();
  }
  if (HAL_TIM_PWM_Init(&htim8) != HAL_OK)
  {
    Error_Handler();
  }
  sSlaveConfig.SlaveMode = TIM_SLAVEMODE_RESET;
  sSlaveConfig.InputTrigger = TIM_TS_ETRF;
  sSlaveConfig.TriggerPolarity = TIM_TRIGGERPOLARITY_NONINVERTED;
  sSlaveConfig.TriggerPrescaler = TIM_TRIGGERPRESCALER_DIV1;
  sSlaveConfig.TriggerFilter = 0;
  if (HAL_TIM_SlaveConfigSynchro(&htim8, &sSlaveConfig) != HAL_OK)
  {
    Error_Handler();
  }
  sMasterConfig.MasterOutputTrigger = TIM_TRGO_RESET;
  sMasterConfig.MasterOutputTrigger2 = TIM_TRGO2_RESET;
  sMasterConfig.MasterSlaveMode = TIM_MASTERSLAVEMODE_DISABLE;
  if (HAL_TIMEx_MasterConfigSynchronization(&htim8, &sMasterConfig) != HAL_OK)
  {
    Error_Handler();
  }
  HAL_TIMEx_RemapConfig(&htim8, TIM_TIM8_ETR_COMP2);
  sConfigOC.OCMode = TIM_OCMODE_PWM1;
  sConfigOC.Pulse = 0;
  sConfigOC.OCPolarity = TIM_OCPOLARITY_HIGH;
  sConfigOC.OCNPolarity = TIM_OCNPOLARITY_HIGH;
  sConfigOC.OCFastMode = TIM_OCFAST_DISABLE;
  sConfigOC.OCIdleState = TIM_OCIDLESTATE_RESET;
  sConfigOC.OCNIdleState = TIM_OCNIDLESTATE_RESET;
  if (HAL_TIM_PWM_ConfigChannel(&htim8, &sConfigOC, TIM_CHANNEL_1) != HAL_OK)
  {
    Error_Handler();
  }
  sBreakDeadTimeConfig.OffStateRunMode = TIM_OSSR_DISABLE;
  sBreakDeadTimeConfig.OffStateIDLEMode = TIM_OSSI_DISABLE;
  sBreakDeadTimeConfig.LockLevel = TIM_LOCKLEVEL_OFF;
  sBreakDeadTimeConfig.DeadTime = 0;
  sBreakDeadTimeConfig.BreakState = TIM_BREAK_DISABLE;
  sBreakDeadTimeConfig.BreakPolarity = TIM_BREAKPOLARITY_HIGH;
  sBreakDeadTimeConfig.BreakFilter = 0;
  sBreakDeadTimeConfig.BreakAFMode = TIM_BREAK_AFMODE_INPUT;
  sBreakDeadTimeConfig.Break2State = TIM_BREAK2_DISABLE;
  sBreakDeadTimeConfig.Break2Polarity = TIM_BREAK2POLARITY_HIGH;
  sBreakDeadTimeConfig.Break2Filter = 0;
  sBreakDeadTimeConfig.Break2AFMode = TIM_BREAK_AFMODE_INPUT;
  sBreakDeadTimeConfig.AutomaticOutput = TIM_AUTOMATICOUTPUT_DISABLE;
  if (HAL_TIMEx_ConfigBreakDeadTime(&htim8, &sBreakDeadTimeConfig) != HAL_OK)
  {
    Error_Handler();
  }

}

static void MX_TIM15_Init(void)
{

  TIM_ClockConfigTypeDef sClockSourceConfig = {0};
  TIM_MasterConfigTypeDef sMasterConfig = {0};

  htim15.Instance = TIM15;
  htim15.Init.Prescaler = 170-1;
  htim15.Init.CounterMode = TIM_COUNTERMODE_UP;
  htim15.Init.Period = 99;
  htim15.Init.ClockDivision = TIM_CLOCKDIVISION_DIV1;
  htim15.Init.RepetitionCounter = 0;
  htim15.Init.AutoReloadPreload = TIM_AUTORELOAD_PRELOAD_DISABLE;
  if (HAL_TIM_Base_Init(&htim15) != HAL_OK)
  {
    Error_Handler();
  }
  sClockSourceConfig.ClockSource = TIM_CLOCKSOURCE_INTERNAL;
  if (HAL_TIM_ConfigClockSource(&htim15, &sClockSourceConfig) != HAL_OK)
  {
    Error_Handler();
  }
  sMasterConfig.MasterOutputTrigger = TIM_TRGO_UPDATE;
  sMasterConfig.MasterSlaveMode = TIM_MASTERSLAVEMODE_DISABLE;
  if (HAL_TIMEx_MasterConfigSynchronization(&htim15, &sMasterConfig) != HAL_OK)
  {
    Error_Handler();
  }

}

static void MX_USART1_UART_Init(void)
{

  huart1.Instance = USART1;
  huart1.Init.BaudRate = 115200;
  huart1.Init.WordLength = UART_WORDLENGTH_8B;
  huart1.Init.StopBits = UART_STOPBITS_1;
  huart1.Init.Parity = UART_PARITY_NONE;
  huart1.Init.Mode = UART_MODE_RX;
  huart1.Init.HwFlowCtl = UART_HWCONTROL_NONE;
  huart1.Init.OverSampling = UART_OVERSAMPLING_16;
  huart1.Init.OneBitSampling = UART_ONE_BIT_SAMPLE_DISABLE;
  huart1.Init.ClockPrescaler = UART_PRESCALER_DIV1;
  huart1.AdvancedInit.AdvFeatureInit = UART_ADVFEATURE_NO_INIT;
  if (HAL_HalfDuplex_Init(&huart1) != HAL_OK)
  {
    Error_Handler();
  }
  if (HAL_UARTEx_SetTxFifoThreshold(&huart1, UART_TXFIFO_THRESHOLD_1_8) != HAL_OK)
  {
    Error_Handler();
  }
  if (HAL_UARTEx_SetRxFifoThreshold(&huart1, UART_RXFIFO_THRESHOLD_1_8) != HAL_OK)
  {
    Error_Handler();
  }
  if (HAL_UARTEx_DisableFifoMode(&huart1) != HAL_OK)
  {
    Error_Handler();
  }

}

static void MX_DMA_Init(void)
{

  /* DMA controller clock enable */
  __HAL_RCC_DMAMUX1_CLK_ENABLE();
  __HAL_RCC_DMA1_CLK_ENABLE();

  /* DMA interrupt init */
  /* DMA1_Channel1_IRQn interrupt configuration */
  HAL_NVIC_SetPriority(DMA1_Channel1_IRQn, 0, 0);
  HAL_NVIC_EnableIRQ(DMA1_Channel1_IRQn);
  /* DMA1_Channel2_IRQn interrupt configuration */
  HAL_NVIC_SetPriority(DMA1_Channel2_IRQn, 0, 0);
  HAL_NVIC_EnableIRQ(DMA1_Channel2_IRQn);

}

static void MX_GPIO_Init(void)
{
  GPIO_InitTypeDef GPIO_InitStruct = {0};

  /* GPIO Ports Clock Enable */
  __HAL_RCC_GPIOF_CLK_ENABLE();
  __HAL_RCC_GPIOA_CLK_ENABLE();
  __HAL_RCC_GPIOB_CLK_ENABLE();

  /*Configure GPIO pin Output Level */
  HAL_GPIO_WritePin(GD_DIS_GPIO_Port, GD_DIS_Pin, GPIO_PIN_RESET);

  /*Configure GPIO pin Output Level */
  HAL_GPIO_WritePin(RELAY_GPIO_Port, RELAY_Pin, GPIO_PIN_RESET);

  /*Configure GPIO pin : GD_DIS_Pin */
  GPIO_InitStruct.Pin = GD_DIS_Pin;
  GPIO_InitStruct.Mode = GPIO_MODE_OUTPUT_PP;
  GPIO_InitStruct.Pull = GPIO_NOPULL;
  GPIO_InitStruct.Speed = GPIO_SPEED_FREQ_LOW;
  HAL_GPIO_Init(GD_DIS_GPIO_Port, &GPIO_InitStruct);

  /*Configure GPIO pin : RELAY_Pin */
  GPIO_InitStruct.Pin = RELAY_Pin;
  GPIO_InitStruct.Mode = GPIO_MODE_OUTPUT_PP;
  GPIO_InitStruct.Pull = GPIO_NOPULL;
  GPIO_InitStruct.Speed = GPIO_SPEED_FREQ_LOW;
  HAL_GPIO_Init(RELAY_GPIO_Port, &GPIO_InitStruct);

}

void Error_Handler(void)
{
  __disable_irq();
  while (1)
  {
  }
}
